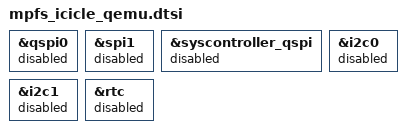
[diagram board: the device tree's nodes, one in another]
/*
 * SPDX-FileCopyrightText: Copyright The Zephyr Project Contributors
 *
 * SPDX-License-Identifier: Apache-2.0
 *
 * Devices the microchip-icicle-kit machine of QEMU does not emulate.
 */

&qspi0 {
	status = "disabled";
};

&spi1 {
	status = "disabled";
};

&syscontroller_qspi {
	status = "disabled";
};

&i2c0 {
	status = "disabled";
};

&i2c1 {
	status = "disabled";
};

&rtc {
	status = "disabled";
};
